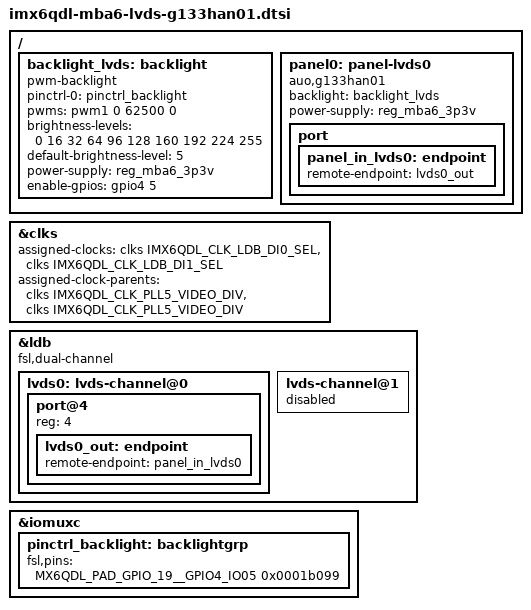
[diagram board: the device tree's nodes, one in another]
// SPDX-License-Identifier: GPL-2.0-only
/*
 * Copyright (c) 2018-2023 TQ-Systems GmbH <linux@ew.tq-group.com>,
 * D-82229 Seefeld, Germany.
 * Author: Markus Niebel <Markus.Niebel@tq-group.com>
 * Author: Alexander Stein <Alexander.Stein@tq-group.com>
 */

/ {
	backlight_lvds: backlight {
		compatible = "pwm-backlight";
		pinctrl-names = "default";
		pinctrl-0 = <&pinctrl_backlight>;
		pwms = <&pwm1 0 62500 0>;
		brightness-levels = <0 16 32 64 96 128 160 192 224 255>;
		default-brightness-level = <5>;
		power-supply = <&reg_mba6_3p3v>;
		enable-gpios = <&gpio4 5 GPIO_ACTIVE_HIGH>;
		status = "okay";
	};

	panel0: panel-lvds0 {
		compatible = "auo,g133han01";
		backlight = <&backlight_lvds>;
		power-supply = <&reg_mba6_3p3v>;

		port {
			panel_in_lvds0: endpoint {
				remote-endpoint = <&lvds0_out>;
			};
		};
	};
};

&clks {
	assigned-clocks = <&clks IMX6QDL_CLK_LDB_DI0_SEL>,
			  <&clks IMX6QDL_CLK_LDB_DI1_SEL>;
	assigned-clock-parents = <&clks IMX6QDL_CLK_PLL5_VIDEO_DIV>,
				 <&clks IMX6QDL_CLK_PLL5_VIDEO_DIV>;
};

&ldb {
	fsl,dual-channel;
	status = "okay";

	lvds0: lvds-channel@0 {
		status = "okay";

		port@4 {
			reg = <4>;

			lvds0_out: endpoint {
				remote-endpoint = <&panel_in_lvds0>;
			};
		};
	};

	lvds-channel@1 {
		status = "disabled";
	};
};

&iomuxc {
	pinctrl_backlight: backlightgrp {
		fsl,pins = <
			/* LCD.BLT_EN */
			MX6QDL_PAD_GPIO_19__GPIO4_IO05 0x0001b099
		>;
	};
};
